# psc3_p8_ppca register map
Vendor: Infineon Technologies; Series: PSC3_P8; File version: 1.0
CPU: CM33 r0p1, little endian, MPU, FPU, DSP, VTOR, 3 interrupt priority bits, 143 interrupts
Registers are 32-bit, read-write, reset 0x0 unless marked. A register's access mark holds for its fields unless they carry their own. Offsets are from the block's base; [hi:lo] are bit positions; lines under a group give offsets from that group; {n}, {i} and the like mark numbered series.

## PPCA_HWFILT3P3Z_SS_0
Base 0x43500000
0x00 CTRL
  [31] HWFILT3P3Z_EN — HWFILT3P3Z_SS0 peripheral enable: 0 = disable (only mmio CTRL registers is accessible) 1 = enable (all AHB registers in the HWFILT3P3Z_SS0 are accessible)
{0x100+0x100*i} HWFILT3P3Z[{i}] (i=0..3) group
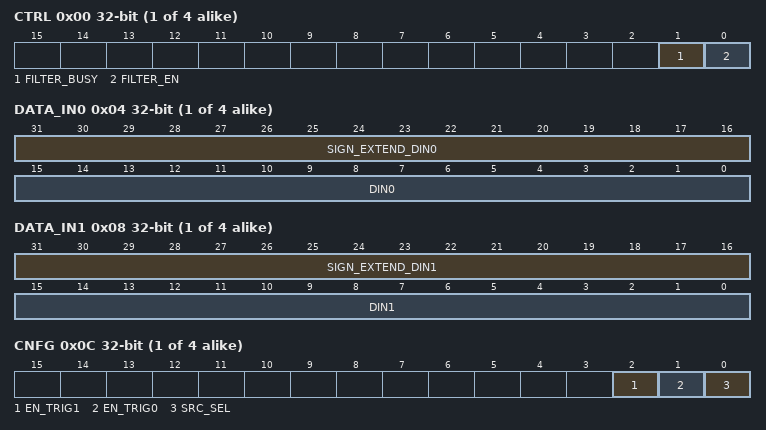
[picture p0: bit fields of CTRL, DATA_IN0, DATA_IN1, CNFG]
  0x00 CTRL
    [1] FILTER_BUSY ro — Filter output ready: 1 = busy 0 = free
    [0] FILTER_EN — Enable/Disable Filter: 0 = Disable (all registers are initilaized to the default values) 1 = Enable
  0x04 DATA_IN0
    [31:16] SIGN_EXTEND_DIN0 ro — Filter Data 0 Input Register sign extended
    [15:0] DIN0 — Filter Data 0 Input Register When writing, the filter processing will start if the corresponding trigger enable bit in the CNFG register is set
  0x08 DATA_IN1
    [31:16] SIGN_EXTEND_DIN1 ro — Filter Data 1 Input Register sign extended
    [15:0] DIN1 — Filter Data 1 Input Register When writing, the filter processing will start if the corresponding trigger enable bit in the CNFG register is set
  0x0C CNFG
    [2] EN_TRIG1 — Enable/Disable filter processing on writing into register DAT_IN1: 0 = Disable 1 = Enable
    [1] EN_TRIG0 — Enable/Disable filter processing on writing into register DAT_IN0: 0 = Disable 1 = Enable
    [0] SRC_SEL — Select source for register DATA_IN1: 0 = AHB IF 1 = DATA PATH
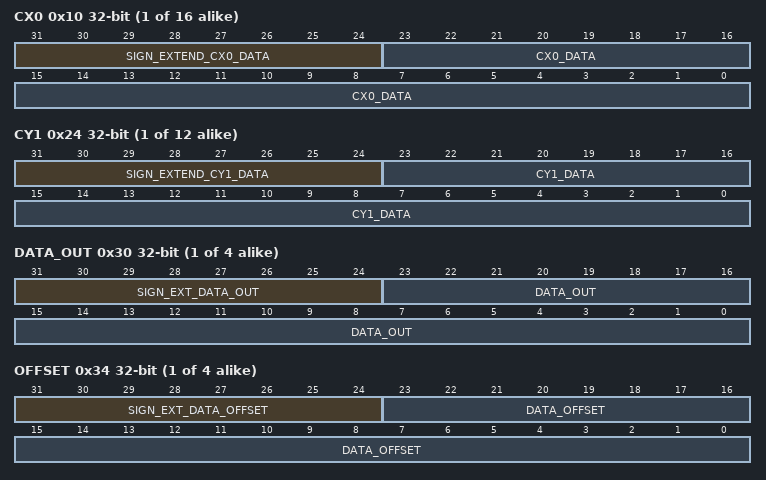
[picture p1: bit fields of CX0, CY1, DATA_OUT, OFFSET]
  {0x10+4j} CX{j} (j=0..3)
    [31:24] SIGN_EXTEND_CX{j}_DATA ro — Coefficient sign extended
    [23:0] CX{j}_DATA — Coefficient data register
  {0x20+4j} CY{j} (j=1..3)
    [31:24] SIGN_EXTEND_CY{j}_DATA ro — Coefficient sign extended
    [23:0] CY{j}_DATA — Coefficient data register
  0x30 DATA_OUT ro
    [31:24] SIGN_EXT_DATA_OUT — Filter Data Output Register sign extended
    [23:0] DATA_OUT — Filter Data Output Register
  0x34 OFFSET
    [31:24] SIGN_EXT_DATA_OFFSET ro — Filter Data Output Offset Register sign extended
    [23:0] DATA_OFFSET — Filter Data Output Offset Register
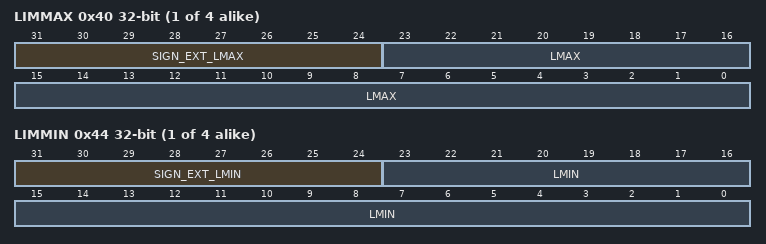
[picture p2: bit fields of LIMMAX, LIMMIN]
  0x40 LIMMAX
    [31:24] SIGN_EXT_LMAX ro — Filter Out Max Limit Register sign extended
    [23:0] LMAX — Filter Out Max Limit Register
  0x44 LIMMIN
    [31:24] SIGN_EXT_LMIN ro — Filter Out Min Limit Register sign extended
    [23:0] LMIN — Filter Out Min Limit Register
  0x60 SCALECX
    [2:0] SCALE_CX — Scale X Coefficients Factor
  0x64 SCALECY
    [2:0] SCALE_CY — Scale Y Coefficients Factor
  0x68 GIN
    [1:0] G_IN — Amplify input difference factor
  0x6C GOUT
    [2:0] G_OUT — Scale down output
  0x80 VERSION ro reset 0xC0DE0001
    [31:0] VERSION — Filter Version Register

## PPCA_HWFILT3P3Z_SS_1
Base 0x43510000
0x00 CTRL
  [31] HWFILT3P3Z_EN — HWFILT3P3Z_SS1 peripheral enable: 0 = disable (only mmio CTRL registers is accessible) 1 = enable (all AHB registers in the HWFILT3P3Z_SS1 are accessible)
{0x100+0x100*i} HWFILT3P3Z[{i}] (i=0..1) group
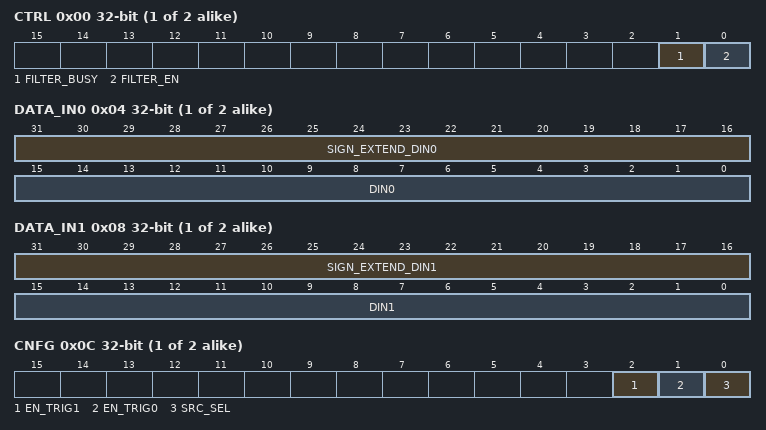
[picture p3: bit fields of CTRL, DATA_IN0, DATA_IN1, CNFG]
  0x00 CTRL
    [1] FILTER_BUSY ro — Filter output ready: 1 = busy 0 = free
    [0] FILTER_EN — Enable/Disable Filter: 0 = Disable (all registers are initilaized to the default values) 1 = Enable
  0x04 DATA_IN0
    [31:16] SIGN_EXTEND_DIN0 ro — Filter Data 0 Input Register sign extended
    [15:0] DIN0 — Filter Data 0 Input Register When writing, the filter processing will start if the corresponding trigger enable bit in the CNFG register is set
  0x08 DATA_IN1
    [31:16] SIGN_EXTEND_DIN1 ro — Filter Data 1 Input Register sign extended
    [15:0] DIN1 — Filter Data 1 Input Register When writing, the filter processing will start if the corresponding trigger enable bit in the CNFG register is set
  0x0C CNFG
    [2] EN_TRIG1 — Enable/Disable filter processing on writing into register DAT_IN1: 0 = Disable 1 = Enable
    [1] EN_TRIG0 — Enable/Disable filter processing on writing into register DAT_IN0: 0 = Disable 1 = Enable
    [0] SRC_SEL — Select source for register DATA_IN1: 0 = AHB IF 1 = DATA PATH
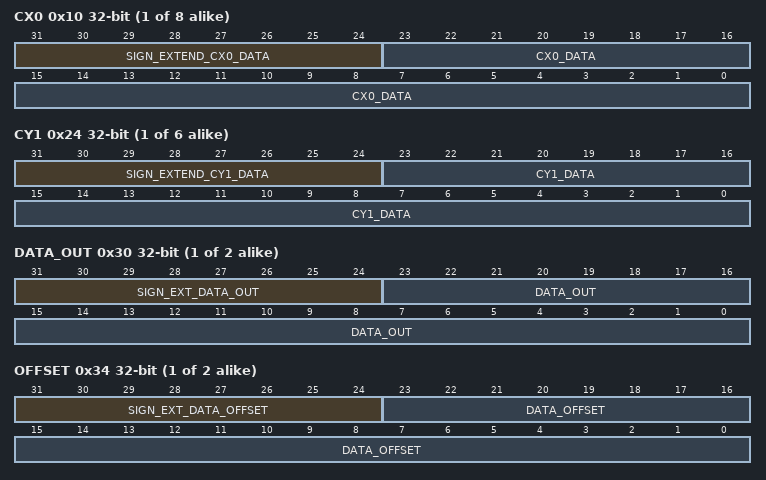
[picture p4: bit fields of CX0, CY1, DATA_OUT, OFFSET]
  {0x10+4j} CX{j} (j=0..3)
    [31:24] SIGN_EXTEND_CX{j}_DATA ro — Coefficient sign extended
    [23:0] CX{j}_DATA — Coefficient data register
  {0x20+4j} CY{j} (j=1..3)
    [31:24] SIGN_EXTEND_CY{j}_DATA ro — Coefficient sign extended
    [23:0] CY{j}_DATA — Coefficient data register
  0x30 DATA_OUT ro
    [31:24] SIGN_EXT_DATA_OUT — Filter Data Output Register sign extended
    [23:0] DATA_OUT — Filter Data Output Register
  0x34 OFFSET
    [31:24] SIGN_EXT_DATA_OFFSET ro — Filter Data Output Offset Register sign extended
    [23:0] DATA_OFFSET — Filter Data Output Offset Register
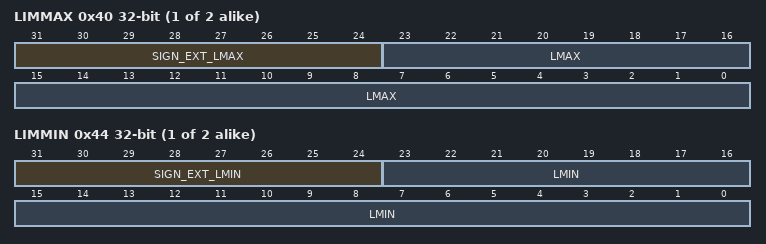
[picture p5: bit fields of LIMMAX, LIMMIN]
  0x40 LIMMAX
    [31:24] SIGN_EXT_LMAX ro — Filter Out Max Limit Register sign extended
    [23:0] LMAX — Filter Out Max Limit Register
  0x44 LIMMIN
    [31:24] SIGN_EXT_LMIN ro — Filter Out Min Limit Register sign extended
    [23:0] LMIN — Filter Out Min Limit Register
  0x60 SCALECX
    [2:0] SCALE_CX — Scale X Coefficients Factor
  0x64 SCALECY
    [2:0] SCALE_CY — Scale Y Coefficients Factor
  0x68 GIN
    [1:0] G_IN — Amplify input difference factor
  0x6C GOUT
    [2:0] G_OUT — Scale down output
  0x80 VERSION ro reset 0xC0DE0001
    [31:0] VERSION — Filter Version Register

## PPCA_ADCM
Base 0x43520000
0x00 ADCM group
  {0x0+4j} ADC_DATA[{j}] (j=0..47) ro
    [31:0] ADC_DATA — ADCs DATA Channel (ADC0_DATA, ADC0_AUX_DATA, ADC0_ALT_AUX_DATA, ADC1_DATA, ADC2_DATA, ADC3_DATA, ADC3_AUX_DATA)

## PPCA_MXCORDIC0
Base 0x43540000
Same registers: PPCA_MXCORDIC1 0x43550000
0x00 CTL
  [31] ENABLED — Enables/Disables IP
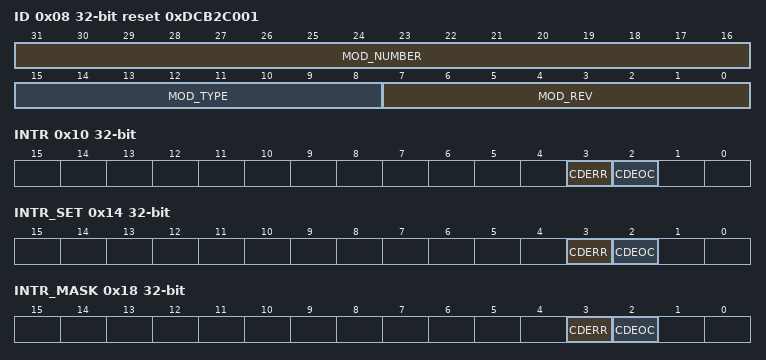
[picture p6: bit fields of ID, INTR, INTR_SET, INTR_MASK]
0x08 ID ro reset 0xDCB2C001 — Module Identification Register
  [31:16] MOD_NUMBER — Module Number Value - MOD_NUMBER
  [15:8] MOD_TYPE — Module Type - MOD_TYPE
  [7:0] MOD_REV — Module Revision Number - MOD_REV
0x10 INTR — Interrupt Cause Register
  [3] CDERR write-1-clears — CORDIC Error Event Flag - CDERR. This bitfield will preserve interrupt cause status also when IP is disabled. By writing '0' to CTL.ENABLED bitfield will not be reset.
  [2] CDEOC write-1-clears — CORDIC End of Calculation Event Flag - CDEOC. This bitfield will preserve interrupt cause status also when IP is disabled. By writing '0' to CTL.ENABLED bitfield will not be reset.
0x14 INTR_SET — Interrupt Set Register
  [3] CDERR write-1-sets — CORDIC Error Event Flag Set - CDERR
  [2] CDEOC write-1-sets — CORDIC Event Flag Set - CDEOC
0x18 INTR_MASK — Interrupt Mask Register
  [3] CDERR — CORDIC Error Interrupt Mask - CDERR
  [2] CDEOC — CORDIC End of Calculation Interrupt Mask- CDEOC
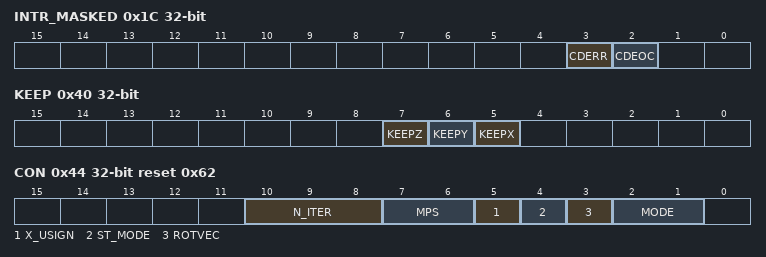
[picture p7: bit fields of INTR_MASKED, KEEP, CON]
0x1C INTR_MASKED ro — Interrupt Masked Register
  [3] CDERR — CORDIC Error Interrupt Masked - CDERR
  [2] CDEOC — CORDIC End of Calculation Interrupt Masked- CDEOC
0x40 KEEP — CORDIC Keep Register
  [7] KEEPZ — Last Z Result as Initial Data for New Calculation - KEEPZ
  [6] KEEPY — Last Y Result as Initial Data for New Calculation - KEEPY
  [5] KEEPX — Last X Result as Initial Data for New Calculation - KEEPX
0x44 CON reset 0x62 — CORDIC Control Register
  [10:8] N_ITER — Number of CORDIC iterations divided by 4
    {v}=N/A (v=1..7)
  [7:6] MPS — X and Y Magnitude Prescaler - MPS
    0=DIVIDE_BY_1 (N/A); 1=DIVIDE_BY_2 (N/A); 2=DIVIDE_BY_4 (N/A); 3=RSVD (N/A)
  [5] X_USIGN — Result Data Format for X in Circular Vectoring Mode - X_USIGN
    0=SIGNED (N/A); 1=UNSIGNED (N/A)
  [4] ST_MODE — Start Method - ST_MODE
    0=AUTO (Operation starts with write into CORDZ register); 1=ST (Operation starts with write into START_CMD register)
  [3] ROTVEC — Rotation Vectoring Selection - ROTVEC
    0=VECTORING (N/A); 1=ROTATION (N/A)
  [2:1] MODE — Operating Mode - MODE
    0=LINEAR (N/A); 1=CIRCULAR (N/A); 2=RSVD (N/A); 3=HYPERBOLIC (N/A)
0x48 CORDX — CORDIC X Data Register
  [31:8] DATA — Initial X Parameter Data - DATA
0x4C CORDY — CORDIC Y Data Register
  [31:8] DATA — Initial Y Parameter Data - DATA
0x50 CORDZ — CORDIC Z Data Register
  [31:8] DATA — Initial Z Parameter Data - DATA
0x54 CORRX ro — CORDIC X Result Register
  [31:8] RESULT — X Calculation Result - RESULT
0x58 CORRY ro — CORDIC Y Result Register
  [31:8] RESULT — Y Calculation Result - RESULT
0x5C CORRZ ro — CORDIC Z Result Register
  [31:8] RESULT — Z Calculation Result - RESULT
0x60 STAT ro — CORDIC Status Register
  [0] BSY — Busy Indication - BSY
0x64 START_CMD — CORDIC Start Command Register
  [0] ST — Start Calculation Set - ST
